# SCRM register map
Vendor: Texas Instruments
Peripheral module from a debugger description file (folder omap4460).
Registers are 32-bit, access per field, reset 0x0 unless marked. A register's access mark holds for its fields unless they carry their own. Offsets are as the file gives them; lines under a group give offsets from that group; [hi:lo] are bit positions; {n}, {i} and the like mark numbered series; 'fields as' and 'values as' point back to an identical list; <NAME> marks a mode.

## SCRM
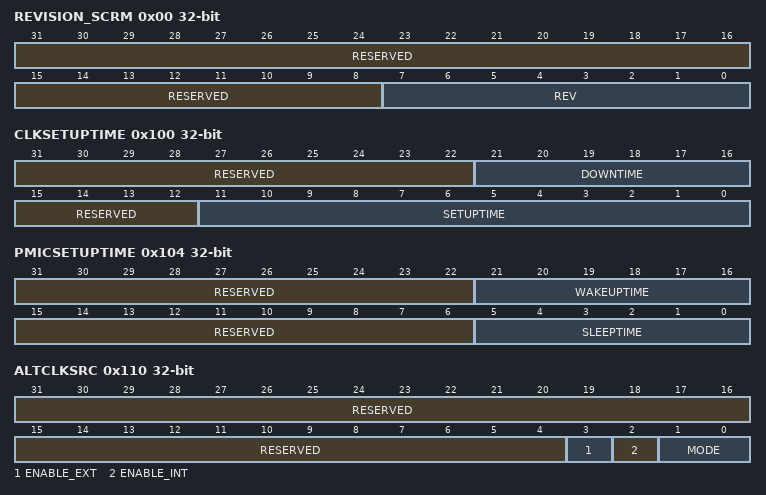
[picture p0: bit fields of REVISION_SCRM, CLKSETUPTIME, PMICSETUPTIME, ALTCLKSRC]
0x00 REVISION_SCRM ro (reset mask 0xFFFFFF00) — This register contains the IP revision code for the SCRM.
  [31:8] RESERVED — Reads returns 0.
  [7:0] REV — Revision Number
0x100 CLKSETUPTIME — This register holds the clock setup time counters of the system clock source supplier.
  [31:22] RESERVED ro — Reads returns 0.
  [21:16] DOWNTIME rw — Holds the number of 32 kHz clock cycles it takes to gate the clock source supplier.
  [15:12] RESERVED ro — Reads returns 0.
  [11:0] SETUPTIME rw — Holds the number of 32 kHz clock cycles it takes to stabilize the clock source supplier.
0x104 PMICSETUPTIME — This register holds the setup time counters for the sleep mode of the PMIC.
  [31:22] RESERVED ro — Reads returns 0.
  [21:16] WAKEUPTIME rw — Holds the number of 32 kHz clock cycles it takes to exit the PMIC from sleep mode.
  [15:6] RESERVED ro — Reads returns 0.
  [5:0] SLEEPTIME rw — Holds the number of 32 kHz clock cycles it takes to enter the PMIC in sleep mode.
0x110 ALTCLKSRC — This register controls the alternate system clock source supplier.
  [31:4] RESERVED ro — Reads returns 0.
  [3] ENABLE_EXT rw — This bit allows to enable and disable the output alternate system clock version. This bit is intended to be used in order to gate this clock path while the source is stabilizing.
    0=The alternate system clock version is disabled; 1=The alternate system clock version is enabled
  [2] ENABLE_INT rw — This bit allows to enable and disable the alternate system clock version used to generate the auxiliary clocks. This bit is intended to be used in order to gate this clock path while the source is stabilizing and also to gate this clock path while switching the auxiliary clock paths on / from this possible source.
    values as ENABLE_EXT
  [1:0] MODE rw — This bit field defines the functional mode of the alternate system clock supplier.
    0=The alternate system clock source supplier is powered-down; 1=The alternate system clock source supplier is active; 2=The alternate system clock source supplier is bypassed
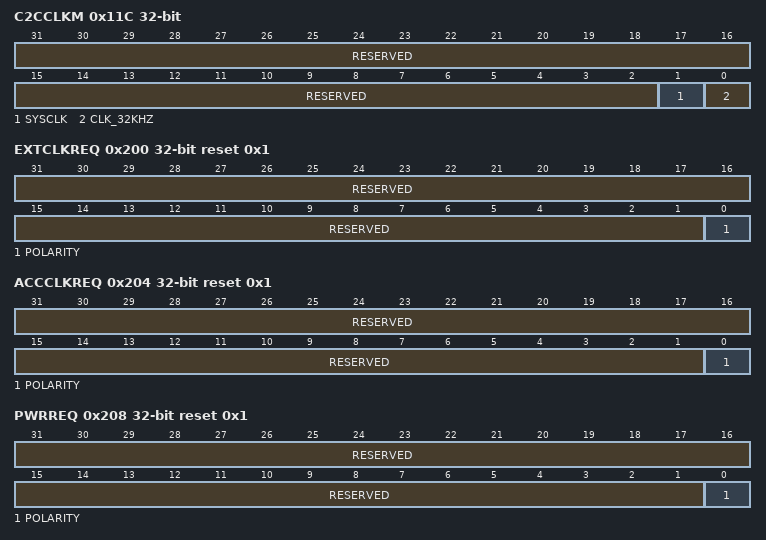
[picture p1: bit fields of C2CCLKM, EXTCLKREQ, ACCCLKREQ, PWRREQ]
0x11C C2CCLKM — This register controls the clocks of the external C2C interface.
  [31:2] RESERVED ro — Reads returns 0.
  [1] SYSCLK rw — This bit allows to enable and disable the system clock version of the external C2C interface.
    0=The system clock version for the external C2C interface is disabled; 1=The system clock version for the external C2C interface is enabled
  [0] CLK_32KHZ rw — This bit allows to enable and disable the 32 kHz clock version of the external C2C interface.
    0=The 32 kHz clock version for the external C2C interface is disabled; 1=The 32 kHz clock version for the external C2C interface is enabled
0x200 EXTCLKREQ reset 0x1 — This register holds qualifiers for the external clock request.
  [31:1] RESERVED ro — Reads returns 0.
  [0] POLARITY rw — This bit defines the active level of the external clock request.
    0=The external clock request is active low; 1=The external clock request is active high
0x204 ACCCLKREQ reset 0x1 — This register holds qualifiers for the accurate clock request.
  [31:1] RESERVED ro — Reads returns 0.
  [0] POLARITY rw — This bit defines the active level of the accurate clock request.
    0=The accurate clock request is active low; 1=The accurate clock request is active high
0x208 PWRREQ reset 0x1 — This register holds qualifiers for the external power request.
  [31:1] RESERVED ro — Reads returns 0.
  [0] POLARITY rw — This bit defines the active level of the external power request.
    0=The external power request is active low; 1=The external power request is active high
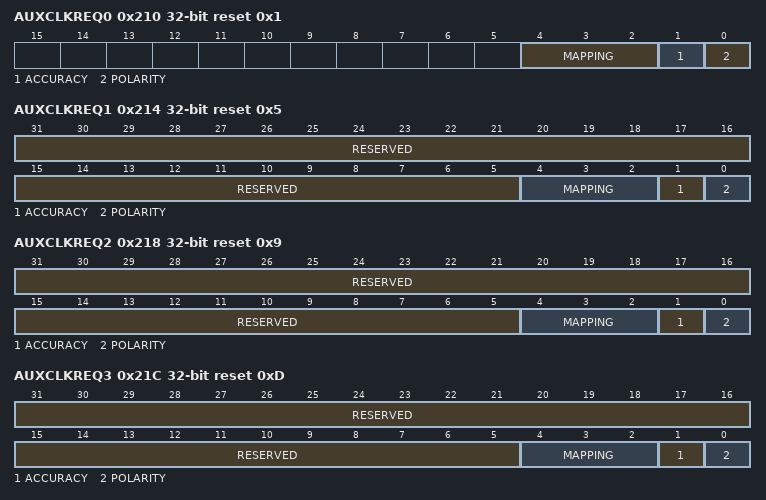
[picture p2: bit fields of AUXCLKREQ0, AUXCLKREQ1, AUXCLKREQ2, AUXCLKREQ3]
0x210 AUXCLKREQ0 reset 0x1 — This register holds qualifiers for the auxiliary clock request #0.
  [4:2] MAPPING rw — This field allows re-mapping the auxiliary clock request #0 on another auxiliary clock output than auxiliary clock #0.
    {v}=The auxiliary clock request #0 is mapped on the auxiliary clock #{v} (v=0..5)
  [1] ACCURACY rw — This bit qualifies the auxiliary clock request #0 as an accurate clock request.
    0=An active auxiliary clock request #0 doesn't generate an accurate clock request; 1=An active auxiliary clock request #0 generates an accurate clock request
  [0] POLARITY rw — This bit defines the active level of the auxiliary clock request #0.
    0=The auxiliary clock request #0 is active low; 1=The auxiliary clock request #0 is active high
0x214 AUXCLKREQ1 reset 0x5 — This register holds qualifiers for the auxiliary clock request #1.
  [31:5] RESERVED ro — Reads returns 0.
  [4:2] MAPPING rw — This field allows re-mapping the auxiliary clock request #1 on another auxiliary clock output than auxiliary clock #1.
    {v}=The auxiliary clock request #1 is mapped on the auxiliary clock #{v} (v=0..5)
  [1] ACCURACY rw — This bit qualifies the auxiliary clock request #1 as an accurate clock request.
    0=An active auxiliary clock request #1 doesn't generate an accurate clock request; 1=An active auxiliary clock request #1 generates an accurate clock request
  [0] POLARITY rw — This bit defines the active level of the auxiliary clock request #1.
    0=The auxiliary clock request #1 is active low; 1=The auxiliary clock request #1 is active high
0x218 AUXCLKREQ2 reset 0x9 — This register holds qualifiers for the auxiliary clock request #2.
  [31:5] RESERVED ro — Reads returns 0.
  [4:2] MAPPING rw — This field allows re-mapping the auxiliary clock request #2 on another auxiliary clock output than auxiliary clock #2.
    {v}=The auxiliary clock request #2 is mapped on the auxiliary clock #{v} (v=0..5)
  [1] ACCURACY rw — This bit qualifies the auxiliary clock request #2 as an accurate clock request.
    0=An active auxiliary clock request #2 doesn't generate an accurate clock request; 1=An active auxiliary clock request #2 generates an accurate clock request
  [0] POLARITY rw — This bit defines the active level of the auxiliary clock request #2.
    0=The auxiliary clock request #2 is active low; 1=The auxiliary clock request #2 is active high
0x21C AUXCLKREQ3 reset 0xD — This register holds qualifiers for the auxiliary clock request #3.
  [31:5] RESERVED ro — Reads returns 0.
  [4:2] MAPPING rw — This field allows re-mapping the auxiliary clock request #3 on another auxiliary clock output than auxiliary clock #3.
    {v}=The auxiliary clock request #3 is mapped on the auxiliary clock #{v} (v=0..5)
  [1] ACCURACY rw — This bit qualifies the auxiliary clock request #3 as an accurate clock request.
    0=An active auxiliary clock request #3 doesn't generate an accurate clock request; 1=An active auxiliary clock request #3 generates an accurate clock request
  [0] POLARITY rw — This bit defines the active level of the auxiliary clock request #3.
    0=The auxiliary clock request #3 is active low; 1=The auxiliary clock request #3 is active high
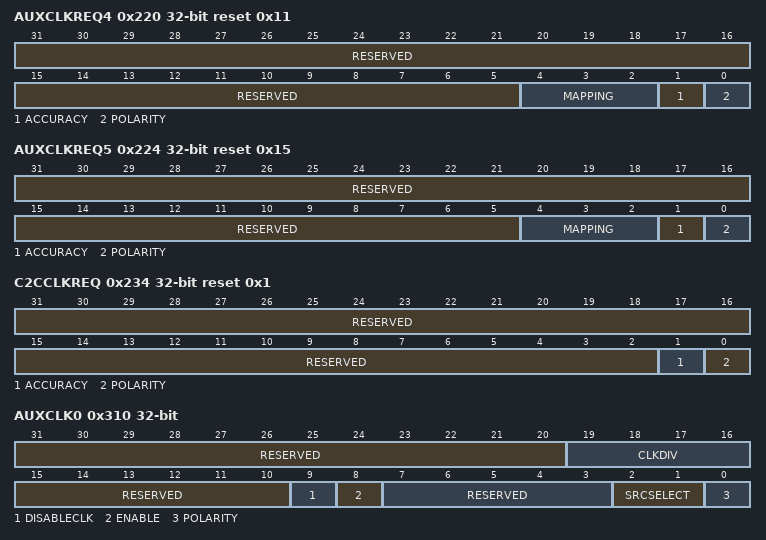
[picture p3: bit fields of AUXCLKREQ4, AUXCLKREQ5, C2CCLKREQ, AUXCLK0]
0x220 AUXCLKREQ4 reset 0x11 — This register holds qualifiers for the auxiliary clock request #4.
  [31:5] RESERVED ro — Reads returns 0.
  [4:2] MAPPING rw — This field allows re-mapping the auxiliary clock request #4 on another auxiliary clock output than auxiliary clock #4.
    {v}=The auxiliary clock request #4 is mapped on the auxiliary clock #{v} (v=0..5)
  [1] ACCURACY rw — This bit qualifies the auxiliary clock request #4 as an accurate clock request.
    0=An active auxiliary clock request #4 doesn't generate an accurate clock request; 1=An active auxiliary clock request #4 generates an accurate clock request
  [0] POLARITY rw — This bit defines the active level of the auxiliary clock request #4.
    0=The auxiliary clock request #4 is active low; 1=The auxiliary clock request #4 is active high
0x224 AUXCLKREQ5 reset 0x15 — This register holds qualifiers for the auxiliary clock request #5.
  [31:5] RESERVED ro — Reads returns 0.
  [4:2] MAPPING rw — This field allows re-mapping the auxiliary clock request #5 on another auxiliary clock output than auxiliary clock #5.
    {v}=The auxiliary clock request #5 is mapped on the auxiliary clock #{v} (v=0..5)
  [1] ACCURACY rw — This bit qualifies the auxiliary clock request #5 as an accurate clock request.
    0=An active auxiliary clock request #5 doesn't generate an accurate clock request; 1=An active auxiliary clock request #5 generates an accurate clock request
  [0] POLARITY rw — This bit defines the active level of the auxiliary clock request #5.
    0=The auxiliary clock request #5 is active low; 1=The auxiliary clock request #5 is active high
0x234 C2CCLKREQ reset 0x1 — This register holds qualifiers for the external C2C interface clock request.
  [31:2] RESERVED ro — Reads returns 0.
  [1] ACCURACY rw — This bit qualifies the external C2C interface clock request as an accurate clock request.
    0=An active external C2C interface clock request doesn't generate an accurate clock request; 1=An active external C2C interface clock request generates an accurate clock request
  [0] POLARITY rw — This bit defines the active level of the external C2C interface clock request.
    0=The external C2C interface clock request is active low; 1=The external C2C interface clock request is active high
0x310 AUXCLK0 — This register holds qualifiers for the auxiliary clock #0.
  [31:20] RESERVED ro — Reads returns 0.
  [19:16] CLKDIV rw — This field holds the divider value for the auxiliary clock #0.
    {v}=The auxiliary clock #0 is divided by {v+1} (v=0..15)
  [15:10] RESERVED ro — Reads returns 0.
  [9] DISABLECLK rw — This bit allows to gate the auxiliary clock #0 without condition. This is bit is intended to be used only when the SOC is not clock provider.
    0=The auxiliary clock #0 is gated upon normal condition: auxiliary clock requests mapped on this path or ENABLE bit set; 1=The auxiliary clock #0 is gated wihout conditon
  [8] ENABLE rw — This bit allows to request the auxiliary clock #0 by software.
    0=The auxiliary clock #0 is not requested by software; 1=The auxiliary clock #0 is requested by software
  [7:3] RESERVED ro — Reads returns 0.
  [2:1] SRCSELECT rw — This field allows selecting the clock source of the auxiliary clock #0.
    0=The clock source is the system clock; 1=The clock source is the version from the CORE DPLL; 2=The clock source is the version from the PER DPLL; 3=The clock source is the alternate clock
  [0] POLARITY rw — This bit defines the output level when the auxiliary clock #0 is gated.
    0=The auxiliary clock #0 is gated low; 1=The auxiliary clock #0 is gated high
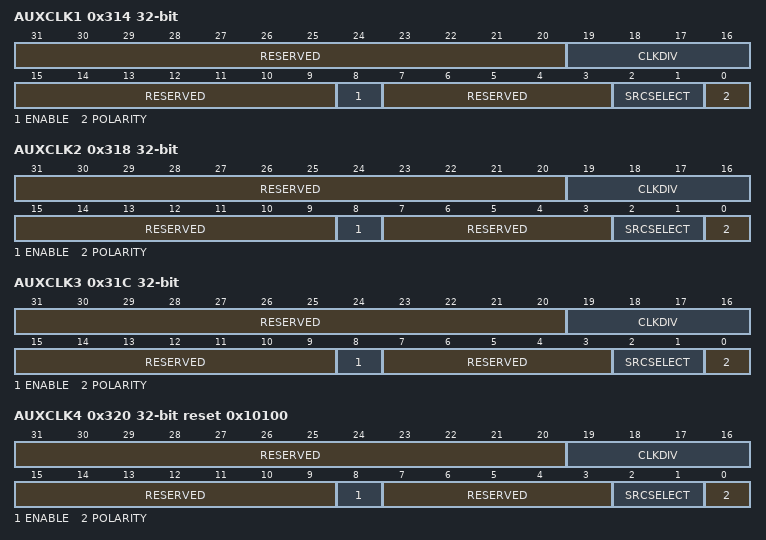
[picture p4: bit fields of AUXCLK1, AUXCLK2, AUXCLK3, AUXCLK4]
0x314 AUXCLK1 — This register holds qualifiers for the auxiliary clock #1.
  [31:20] RESERVED ro — Reads returns 0.
  [19:16] CLKDIV rw — This field holds the divider value for the auxiliary clock #1.
    {v}=The auxiliary clock #1 is divided by {v+1} (v=0..15)
  [15:9] RESERVED ro — Reads returns 0.
  [8] ENABLE rw — This bit allows to request the auxiliary clock #1 by software.
    0=The auxiliary clock #1 is not requested by software; 1=The auxiliary clock #1 is requested by software
  [7:3] RESERVED ro — Reads returns 0.
  [2:1] SRCSELECT rw — This field allows selecting the clock source of the auxiliary clock #1.
    values as AUXCLK0.SRCSELECT
  [0] POLARITY rw — This bit defines the output level when the auxiliary clock #1 is gated.
    0=The auxiliary clock #1 is gated low; 1=The auxiliary clock #1 is gated high
0x318 AUXCLK2 — This register holds qualifiers for the auxiliary clock #2.
  [31:20] RESERVED ro — Reads returns 0.
  [19:16] CLKDIV rw — This field holds the divider value for the auxiliary clock #2.
    {v}=The auxiliary clock #2 is divided by {v+1} (v=0..15)
  [15:9] RESERVED ro — Reads returns 0.
  [8] ENABLE rw — This bit allows to request the auxiliary clock #2 by software.
    0=The auxiliary clock #2 is not requested by software; 1=The auxiliary clock #2 is requested by software
  [7:3] RESERVED ro — Reads returns 0.
  [2:1] SRCSELECT rw — This field allows selecting the clock source of the auxiliary clock #2.
    values as AUXCLK0.SRCSELECT
  [0] POLARITY rw — This bit defines the output level when the auxiliary clock #2 is gated.
    0=The auxiliary clock #2 is gated low; 1=The auxiliary clock #2 is gated high
0x31C AUXCLK3 — This register holds qualifiers for the auxiliary clock #3.
  [31:20] RESERVED ro — Reads returns 0.
  [19:16] CLKDIV rw — This field holds the divider value for the auxiliary clock #3.
    {v}=The auxiliary clock #3 is divided by {v+1} (v=0..15)
  [15:9] RESERVED ro — Reads returns 0.
  [8] ENABLE rw — This bit allows to request the auxiliary clock #3 by software.
    0=The auxiliary clock #3 is disabled by software; 1=The auxiliary clock #3 is requested by software
  [7:3] RESERVED ro — Reads returns 0.
  [2:1] SRCSELECT rw — This field allows selecting the clock source of the auxiliary clock #3.
    values as AUXCLK0.SRCSELECT
  [0] POLARITY rw — This bit defines the output level when the auxiliary clock #3 is gated.
    0=The auxiliary clock #3 is gated low; 1=The auxiliary clock #3 is gated high
0x320 AUXCLK4 reset 0x10100 — This register holds qualifiers for the auxiliary clock #4.
  [31:20] RESERVED ro — Reads returns 0.
  [19:16] CLKDIV rw — This field holds the divider value for the auxiliary clock #4.
    {v}=The auxiliary clock #4 is divided by {v+1} (v=0..15)
  [15:9] RESERVED ro — Reads returns 0.
  [8] ENABLE rw — This bit allows to request the auxiliary clock #4 by software.
    0=The auxiliary clock #4 is not requested by software; 1=The auxiliary clock #4 is requested by software
  [7:3] RESERVED ro — Reads returns 0.
  [2:1] SRCSELECT rw — This field allows selecting the clock source of the auxiliary clock #4.
    values as AUXCLK0.SRCSELECT
  [0] POLARITY rw — This bit defines the output level when the auxiliary clock #4 is gated.
    0=The auxiliary clock #4 is gated low; 1=The auxiliary clock #4 is gated high
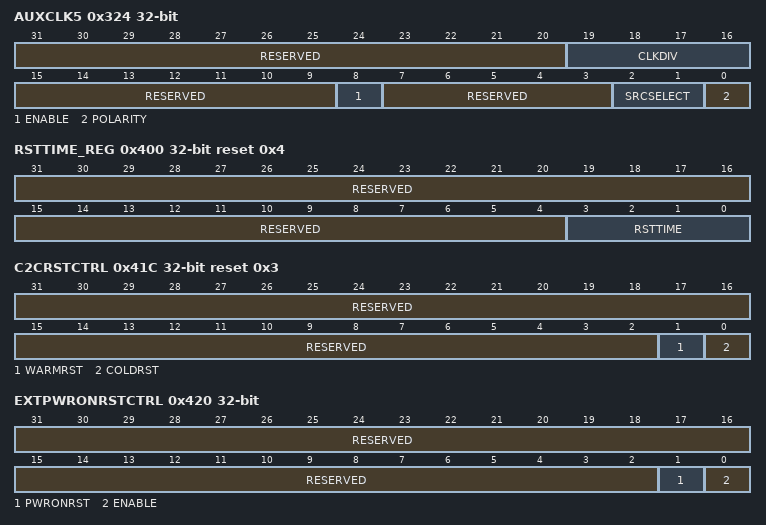
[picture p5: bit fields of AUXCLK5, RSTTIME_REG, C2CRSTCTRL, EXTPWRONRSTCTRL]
0x324 AUXCLK5 — This register holds qualifiers for the auxiliary clock #5.
  [31:20] RESERVED ro — Reads returns 0.
  [19:16] CLKDIV rw — This field holds the divider value for the auxiliary clock #5.
    {v}=The auxiliary clock #5 is divided by {v+1} (v=0..15)
  [15:9] RESERVED ro — Reads returns 0.
  [8] ENABLE rw — This bit allows to request the auxiliary clock #5 by software.
    0=The auxiliary clock #5 is not requested by software; 1=The auxiliary clock #5 is requested by software
  [7:3] RESERVED ro — Reads returns 0.
  [2:1] SRCSELECT rw — This field allows selecting the clock source of the auxiliary clock #5.
    values as AUXCLK0.SRCSELECT
  [0] POLARITY rw — This bit defines the output level when the auxiliary clock #5 is gated.
    0=The auxiliary clock #5 is gated low; 1=The auxiliary clock #5 is gated high
0x400 RSTTIME_REG reset 0x4 — This register holds the reset time counter which is used to extend the reset lines beyond the release of the pad reset.
  [31:4] RESERVED ro — Reads returns 0.
  [3:0] RSTTIME rw — Holds the number of 32 kHz clock cycles for which the reset duration is extended. Values 0,1 and 2 are not allowed. 0x0: Reserved. 0x1: Reserved. 0x2: Reserved.
0x41C C2CRSTCTRL reset 0x3 — This register controls the release of the external C2C interface reset lines.
  [31:2] RESERVED ro — Reads returns 0.
  [1] WARMRST rw — This bit allows to release the warm reset line of the external C2C interface. [warm reset sensitive]
    0=Clearing this bit has for effect to release the warm reset line of the external C2C interface; 1=Writing this bit has for effect to assert the warm reset line of the external C2C interface
  [0] COLDRST rw — This bit allows to release the cold reset line of the external C2C interface.
    0=Clearing this bit has for effect to release the cold reset line of the external C2C interface; 1=Writing this bit has for effect to assert the cold reset line of the external C2C interface
0x420 EXTPWRONRSTCTRL access not given — This register allows the software to perform an external power-on reset.
  [31:2] RESERVED ro — Reads returns 0.
  [1] PWRONRST — This bit controls the assertion and the de-assertion of the external power-on reset. (access RW WSpecial)
    0=De-asserts the external power-on reset; 1=Asserts the external power-on reset
  [0] ENABLE — This bit must be set to 1 to allow the software to assert the external power-on reset. (access RW WSpecial)
    0=Prevents the software to assert the external power-on reset; 1=Allows the software to assert the external power-on reset
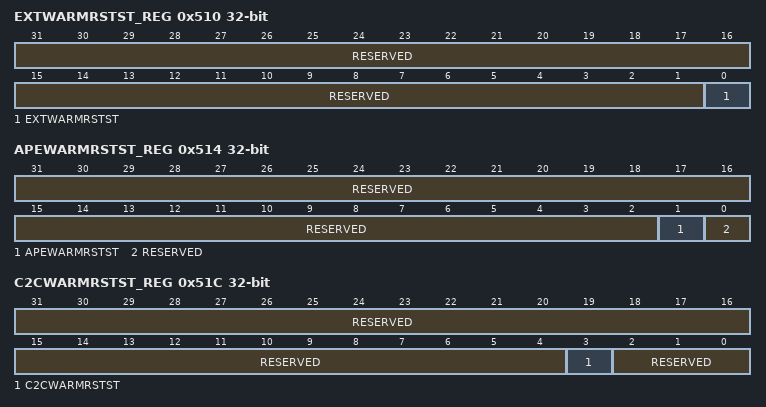
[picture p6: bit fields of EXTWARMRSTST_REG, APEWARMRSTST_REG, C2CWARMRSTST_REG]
0x510 EXTWARMRSTST_REG access not given — This register logs the source of warm reset output. Each bit is set upon release of the warm reset output and must be cleared by software.
  [31:1] RESERVED ro — Reads returns 0.
  [0] EXTWARMRSTST — This bit logs the external warm reset source. (access RW W1toClr)
    0=No external warm reset occurred; 1=An external warm reset occurred
0x514 APEWARMRSTST_REG access not given — This register logs the source of warm reset on the APE. Each bit is set upon release of the APE warm reset and must be cleared by software.
  [31:2] RESERVED ro — Reads returns 0.
  [1] APEWARMRSTST — This bit logs the APE warm reset source. (access RW W1toClr)
    0=No APE warm reset occurred; 1=An APE warm reset occurred
  [0] RESERVED ro — Reads returns 0.
0x51C C2CWARMRSTST_REG access not given — This register logs the source of warm reset on the external C2C interface. Each bit is set upon release of the external C2C interface warm reset and must be cleared by software.
  [31:4] RESERVED ro — Reads returns 0.
  [3] C2CWARMRSTST — This bit logs the C2C warm reset source. (access RW W1toClr)
    0=No C2C warm reset occurred; 1=A C2C warm reset occurred
  [2:0] RESERVED ro — Reads returns 0.
